# MKM34ZA5 register map
Vendor: Freescale Semiconductor, Inc.; Series: Kinetis_M; File version: 1.6
CPU: CM0PLUS r0p0, little endian, no MPU, no FPU, VTOR, 2 interrupt priority bits
Registers are 8-bit, read-write, reset 0x0 unless marked. A register's access mark holds for its fields unless they carry their own. Offsets are from the block's base; [hi:lo] are bit positions; {n}, {i} and the like mark numbered series; 'fields as' and 'values as' point back to an identical list.

## PORTD — Pin Control and Interrupts
Base 0x40049000; register names take the prefix PORTD_
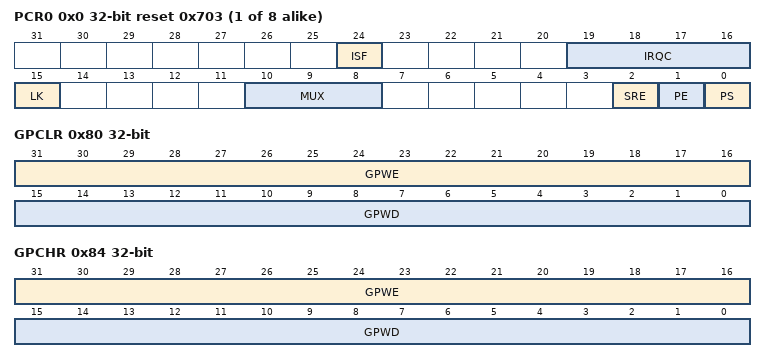
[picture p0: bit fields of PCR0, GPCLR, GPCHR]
{0x0+4i} PCR{i} (i=0..7) 32-bit reset 0x703 — Pin Control Register n
  [24] ISF — Interrupt Status Flag
    0=Configured interrupt is not detected; 1=Configured interrupt is detected. If the pin is configured to generate a DMA request, then the corresponding flag will be cleared automatically at the completion of the requested DMA transfer. Otherwise, the flag remains set until a logic one is written to the flag. If the pin is configured for a level sensitive interrupt and the pin remains asserted, then the flag is set again immediately after it is cleared.
  [19:16] IRQC — Interrupt Configuration
    0=Interrupt/DMA request disabled; 1=DMA request on rising edge; 2=DMA request on falling edge; 3=DMA request on either edge; 8=Interrupt when logic zero; 9=Interrupt on rising edge; 10=Interrupt on falling edge; 11=Interrupt on either edge; 12=Interrupt when logic one
  [15] LK — Lock Register
    0=Pin Control Register fields [15:0] are not locked; 1=Pin Control Register fields [15:0] are locked and cannot be updated until the next system reset
  [10:8] MUX — Pin Mux Control
    0=Pin disabled (analog); 1=Alternative 1 (GPIO); {v}=Alternative {v} (chip-specific) (v=2..7)
  [2] SRE — Slew Rate Enable
    0=Fast slew rate is configured on the corresponding pin, if the pin is configured as a digital output; 1=Slow slew rate is configured on the corresponding pin, if the pin is configured as a digital output
  [1] PE — Pull Enable
    0=Internal pullup or pulldown resistor is not enabled on the corresponding pin; 1=Internal pullup or pulldown resistor is enabled on the corresponding pin, if the pin is configured as a digital input
  [0] PS — Pull Select
    0=Internal pulldown resistor is enabled on the corresponding pin, if the corresponding Port Pull Enable field is set; 1=Internal pullup resistor is enabled on the corresponding pin, if the corresponding Port Pull Enable field is set
0x80 GPCLR 32-bit wo — Global Pin Control Low Register
  [31:16] GPWE — Global Pin Write Enable
    0=Corresponding Pin Control Register is not updated with the value in GPWD; 1=Corresponding Pin Control Register is updated with the value in GPWD
  [15:0] GPWD — Global Pin Write Data
0x84 GPCHR 32-bit wo — Global Pin Control High Register
  fields as GPCLR
0xA0 ISFR 32-bit — Interrupt Status Flag Register
  [31:0] ISF — Interrupt Status Flag
    values as PCR0.ISF

## XBAR — Crossbar Switch
Base 0x40055000; register names take the prefix XBAR_
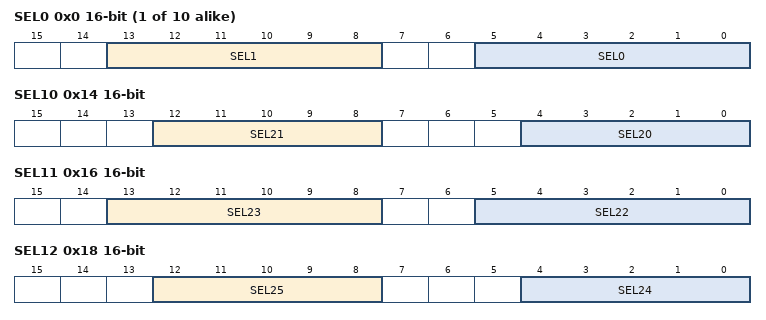
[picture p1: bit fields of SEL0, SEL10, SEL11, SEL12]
{0x0+2i} SEL{i} 16-bit (i=0..9) — Crossbar Select Register {i}
  [13:8] SEL{2i+1} — Input (XBAR_INn) to be muxed to XBAR_OUT{2i+1} (refer to Functional Description section for input/output assignment)
  [5:0] SEL{2i} — Input (XBAR_INn) to be muxed to XBAR_OUT{2i} (refer to Functional Description section for input/output assignment)
0x14 SEL10 16-bit — Crossbar Select Register 10
  [12:8] SEL21 — Input (XBAR_INn) to be muxed to XBAR_OUT21 (refer to Functional Description section for input/output assignment)
  [4:0] SEL20 — Input (XBAR_INn) to be muxed to XBAR_OUT20 (refer to Functional Description section for input/output assignment)
0x16 SEL11 16-bit — Crossbar Select Register 11
  [13:8] SEL23 — Input (XBAR_INn) to be muxed to XBAR_OUT23 (refer to Functional Description section for input/output assignment)
  [5:0] SEL22 — Input (XBAR_INn) to be muxed to XBAR_OUT22 (refer to Functional Description section for input/output assignment)
0x18 SEL12 16-bit — Crossbar Select Register 12
  [12:8] SEL25 — Input (XBAR_INn) to be muxed to XBAR_OUT25 (refer to Functional Description section for input/output assignment)
  [4:0] SEL24 — Input (XBAR_INn) to be muxed to XBAR_OUT24 (refer to Functional Description section for input/output assignment)
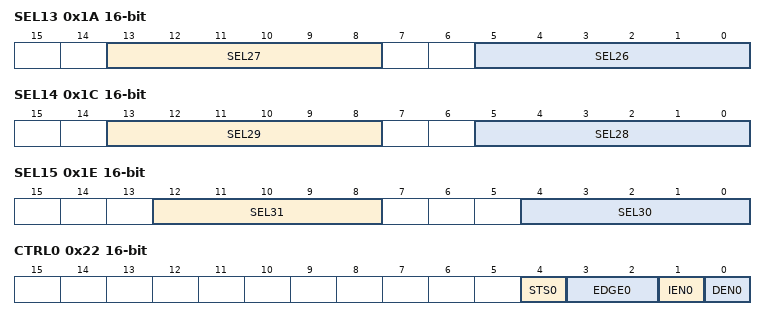
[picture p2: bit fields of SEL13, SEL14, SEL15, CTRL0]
0x1A SEL13 16-bit — Crossbar Select Register 13
  [13:8] SEL27 — Input (XBAR_INn) to be muxed to XBAR_OUT27 (refer to Functional Description section for input/output assignment)
  [5:0] SEL26 — Input (XBAR_INn) to be muxed to XBAR_OUT26 (refer to Functional Description section for input/output assignment)
0x1C SEL14 16-bit — Crossbar Select Register 14
  [13:8] SEL29 — Input (XBAR_INn) to be muxed to XBAR_OUT29 (refer to Functional Description section for input/output assignment)
  [5:0] SEL28 — Input (XBAR_INn) to be muxed to XBAR_OUT28 (refer to Functional Description section for input/output assignment)
0x1E SEL15 16-bit — Crossbar Select Register 15
  [12:8] SEL31 — Input (XBAR_INn) to be muxed to XBAR_OUT31 (refer to Functional Description section for input/output assignment)
  [4:0] SEL30 — Input (XBAR_INn) to be muxed to XBAR_OUT30 (refer to Functional Description section for input/output assignment)
0x20 SEL16 16-bit — Crossbar Select Register 16
  [5:0] SEL32 — Input (XBAR_INn) to be muxed to XBAR_OUT32 (refer to Functional Description section for input/output assignment)
0x22 CTRL0 16-bit — Crossbar Control Register 0
  [4] STS0 — Edge detection status for XBAR_OUT0
    0=Active edge not yet detected on XBAR_OUT0; 1=Active edge detected on XBAR_OUT0
  [3:2] EDGE0 — Active edge for edge detection on XBAR_OUT0
    0=STS0 never asserts; 1=STS0 asserts on rising edges of XBAR_OUT0; 2=STS0 asserts on falling edges of XBAR_OUT0; 3=STS0 asserts on rising and falling edges of XBAR_OUT0
  [1] IEN0 — Interrupt Enable for XBAR_OUT0
    0=Interrupt disabled; 1=Interrupt enabled
  [0] DEN0 — DMA Enable for XBAR_OUT0
    0=DMA disabled; 1=DMA enabled
